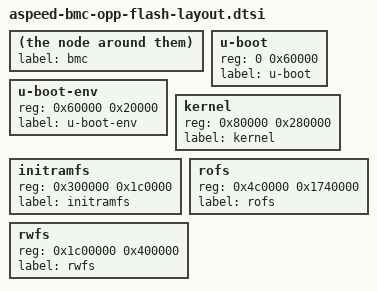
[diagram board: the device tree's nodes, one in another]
/* This file is the label for the bmc primary flash and its partitions */
				label = "bmc";
				#address-cells = < 1 >;
				#size-cells = < 1 >;
				u-boot {
					reg = < 0 0x60000 >;
					label = "u-boot";
				};
				u-boot-env {
					reg = < 0x60000 0x20000 >;
					label = "u-boot-env";
				};
				kernel  {
					reg = < 0x80000 0x280000 >;
					label = "kernel";
				};
				initramfs {
					reg = < 0x300000 0x1c0000 >;
					label = "initramfs";
				};
				rofs  {
					reg = < 0x4c0000 0x1740000 >;
					label = "rofs";
				};
				rwfs  {
					reg = < 0x1c00000 0x400000 >;
					label = "rwfs";
				};
